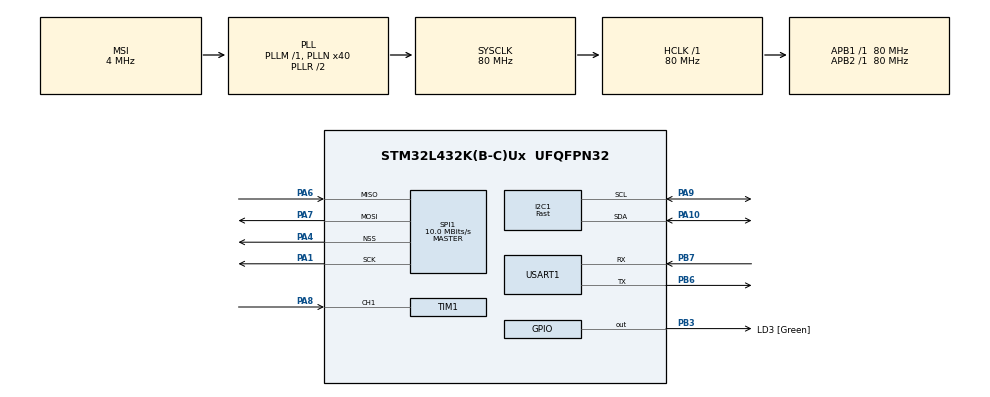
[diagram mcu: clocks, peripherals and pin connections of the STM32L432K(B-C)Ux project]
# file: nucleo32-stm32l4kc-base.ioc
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I2C1.I2C_Speed_Mode=I2C_Fast
I2C1.Timing=0x00702991
Mcu.Family=STM32L4
Mcu.Name=STM32L432K(B-C)Ux
Mcu.Package=UFQFPN32
NVIC.I2C1_ER_IRQn=true\:0\:0\:false\:false\:true\:true
NVIC.I2C1_EV_IRQn=true\:0\:0\:false\:false\:true\:true
NVIC.PriorityGroup=NVIC_PRIORITYGROUP_4
NVIC.SPI1_IRQn=true\:0\:0\:false\:false\:true\:true
NVIC.TIM1_CC_IRQn=true\:0\:0\:false\:false\:true\:true
NVIC.USART1_IRQn=true\:0\:0\:false\:false\:true\:true
PA0.GPIO_Label=MCO [High speed clock in]
PA0.Signal=RCC_CK_IN
PA1.Mode=Full_Duplex_Master
PA1.Signal=SPI1_SCK
PA10.Mode=I2C
PA10.Signal=I2C1_SDA
PA13\ (JTMS-SWDIO).GPIO_Label=SWDIO
PA13\ (JTMS-SWDIO).Signal=SYS_JTMS-SWDIO
PA14\ (JTCK-SWCLK).GPIO_Label=SWCLK
PA14\ (JTCK-SWCLK).Signal=SYS_JTCK-SWCLK
PA15\ (JTDI).GPIO_Label=VCP_RX
PA15\ (JTDI).Signal=USART2_RX
PA2.GPIO_Label=VCP_TX
PA2.Signal=USART2_TX
PA4.Mode=NSS_Signal_Hard_Output
PA4.Signal=SPI1_NSS
PA6.Mode=Full_Duplex_Master
PA6.Signal=SPI1_MISO
PA7.Mode=Full_Duplex_Master
PA7.Signal=SPI1_MOSI
PA8.Signal=S_TIM1_CH1
PA9.Mode=I2C
PA9.Signal=I2C1_SCL
PB3\ (JTDO-TRACESWO).GPIO_Label=LD3 [Green]
PB3\ (JTDO-TRACESWO).Signal=GPIO_Output
PB6.Mode=Asynchronous
PB6.Signal=USART1_TX
PB7.Mode=Asynchronous
PB7.Signal=USART1_RX
PC14-OSC32_IN\ (PC14).Signal=RCC_OSC32_IN
PC15-OSC32_OUT\ (PC15).Signal=RCC_OSC32_OUT
ProjectManager.HeapSize=0x200
ProjectManager.StackSize=0x400
ProjectManager.TargetToolchain=Makefile
RCC.AHBFreq_Value=80000000
RCC.APB1Freq_Value=80000000
RCC.APB1TimFreq_Value=80000000
RCC.APB2Freq_Value=80000000
RCC.APB2TimFreq_Value=80000000
RCC.CortexFreq_Value=80000000
RCC.HCLKFreq_Value=80000000
RCC.HSE_VALUE=8000000
RCC.HSI16_VALUE=16000000
RCC.HSI48_VALUE=48000000
RCC.HSI_VALUE=16000000
RCC.LSE_VALUE=32768
RCC.MSI_VALUE=4000000
RCC.PLLMUL=RCC_PLLMUL_4
RCC.PLLN=40
RCC.SYSCLKFreq_VALUE=80000000
RCC.SYSCLKSource=RCC_SYSCLKSOURCE_PLLCLK
RCC.VCOOutputFreq_Value=160000000
SH.S_TIM1_CH1.0=TIM1_CH1,Input_Capture1_from_TI1
SPI1.BaudRatePrescaler=SPI_BAUDRATEPRESCALER_8
SPI1.CalculateBaudRate=10.0 MBits/s
SPI1.Direction=SPI_DIRECTION_2LINES
SPI1.Mode=SPI_MODE_MASTER
SPI1.VirtualNSS=VM_NSSHARD
SPI1.VirtualType=VM_MASTER
TIM1.AutoReloadPreload=TIM_AUTORELOAD_PRELOAD_ENABLE
TIM1.Channel-Input_Capture1_from_TI1=TIM_CHANNEL_1
TIM1.Period=60000
TIM1.Prescaler=256
USART1.VirtualMode-Asynchronous=VM_ASYNC
VP_TIM1_VS_ClockSourceINT.Mode=Internal
board=NUCLEO-L432KC

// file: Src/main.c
/**
  ******************************************************************************
  * File Name          : main.c
  * Description        : Main program body
  ******************************************************************************
  ** This notice applies to any and all portions of this file
  * that are not between comment pairs USER CODE BEGIN and
  * USER CODE END. Other portions of this file, whether
  * inserted by the user or by software development tools
  * are owned by their respective copyright owners.
  *
  * COPYRIGHT(c) 2018 STMicroelectronics
  *
  * Redistribution and use in source and binary forms, with or without modification,
  * are permitted provided that the following conditions are met:
  *   1. Redistributions of source code must retain the above copyright notice,
  *      this list of conditions and the following disclaimer.
  *   2. Redistributions in binary form must reproduce the above copyright notice,
  *      this list of conditions and the following disclaimer in the documentation
  *      and/or other materials provided with the distribution.
  *   3. Neither the name of STMicroelectronics nor the names of its contributors
  *      may be used to endorse or promote products derived from this software
  *      without specific prior written permission.
  *
  * THIS SOFTWARE IS PROVIDED BY THE COPYRIGHT HOLDERS AND CONTRIBUTORS "AS IS"
  * AND ANY EXPRESS OR IMPLIED WARRANTIES, INCLUDING, BUT NOT LIMITED TO, THE
  * IMPLIED WARRANTIES OF MERCHANTABILITY AND FITNESS FOR A PARTICULAR PURPOSE ARE
  * DISCLAIMED. IN NO EVENT SHALL THE COPYRIGHT HOLDER OR CONTRIBUTORS BE LIABLE
  * FOR ANY DIRECT, INDIRECT, INCIDENTAL, SPECIAL, EXEMPLARY, OR CONSEQUENTIAL
  * DAMAGES (INCLUDING, BUT NOT LIMITED TO, PROCUREMENT OF SUBSTITUTE GOODS OR
  * SERVICES; LOSS OF USE, DATA, OR PROFITS; OR BUSINESS INTERRUPTION) HOWEVER
  * CAUSED AND ON ANY THEORY OF LIABILITY, WHETHER IN CONTRACT, STRICT LIABILITY,
  * OR TORT (INCLUDING NEGLIGENCE OR OTHERWISE) ARISING IN ANY WAY OUT OF THE USE
  * OF THIS SOFTWARE, EVEN IF ADVISED OF THE POSSIBILITY OF SUCH DAMAGE.
  *
  ******************************************************************************
  */

#include "main.h"
#include "stm32l4xx_hal.h"
#include "i2c.h"
#include "spi.h"
#include "tim.h"
#include "usart.h"
#include "gpio.h"

/* USER CODE BEGIN PV */
/* Private variables ---------------------------------------------------------*/

/* USER CODE END PV */

void SystemClock_Config(void);

/* USER CODE BEGIN PFP */
/* Private function prototypes -----------------------------------------------*/

/* USER CODE END PFP */

int main(void) {

    /* MCU Configuration----------------------------------------------------------*/

    /* Reset of all peripherals, Initializes the Flash interface and the Systick. */
    HAL_Init();

    /* Configure the system clock */
    SystemClock_Config();

    /* Initialize all configured peripherals */
    MX_GPIO_Init();
    MX_I2C1_Init();
    MX_SPI1_Init();
    MX_USART1_UART_Init();
    MX_TIM1_Init();

    /* Infinite loop */
    while (1) {

        while (1) {

            HAL_Delay(100);
            HAL_GPIO_TogglePin(LD3_GPIO_Port, LD3_Pin);
        }

    }

}

/** System Clock Configuration
*/
void SystemClock_Config(void) {

    RCC_OscInitTypeDef RCC_OscInitStruct;
    RCC_ClkInitTypeDef RCC_ClkInitStruct;
    RCC_PeriphCLKInitTypeDef PeriphClkInit;

    /**Initializes the CPU, AHB and APB busses clocks
    */
    RCC_OscInitStruct.OscillatorType = RCC_OSCILLATORTYPE_MSI;
    RCC_OscInitStruct.MSIState = RCC_MSI_ON;
    RCC_OscInitStruct.MSICalibrationValue = 0;
    RCC_OscInitStruct.MSIClockRange = RCC_MSIRANGE_6;
    RCC_OscInitStruct.PLL.PLLState = RCC_PLL_ON;
    RCC_OscInitStruct.PLL.PLLSource = RCC_PLLSOURCE_MSI;
    RCC_OscInitStruct.PLL.PLLM = 1;
    RCC_OscInitStruct.PLL.PLLN = 40;
    RCC_OscInitStruct.PLL.PLLP = RCC_PLLP_DIV7;
    RCC_OscInitStruct.PLL.PLLQ = RCC_PLLQ_DIV2;
    RCC_OscInitStruct.PLL.PLLR = RCC_PLLR_DIV2;
    if (HAL_RCC_OscConfig(&RCC_OscInitStruct) != HAL_OK) {
        _Error_Handler(__FILE__, __LINE__);
    }

    /**Initializes the CPU, AHB and APB busses clocks
    */
    RCC_ClkInitStruct.ClockType = RCC_CLOCKTYPE_HCLK | RCC_CLOCKTYPE_SYSCLK
                                  | RCC_CLOCKTYPE_PCLK1 | RCC_CLOCKTYPE_PCLK2;
    RCC_ClkInitStruct.SYSCLKSource = RCC_SYSCLKSOURCE_PLLCLK;
    RCC_ClkInitStruct.AHBCLKDivider = RCC_SYSCLK_DIV1;
    RCC_ClkInitStruct.APB1CLKDivider = RCC_HCLK_DIV1;
    RCC_ClkInitStruct.APB2CLKDivider = RCC_HCLK_DIV1;

    if (HAL_RCC_ClockConfig(&RCC_ClkInitStruct, FLASH_LATENCY_4) != HAL_OK) {
        _Error_Handler(__FILE__, __LINE__);
    }

    PeriphClkInit.PeriphClockSelection = RCC_PERIPHCLK_USART1 | RCC_PERIPHCLK_I2C1;
    PeriphClkInit.Usart1ClockSelection = RCC_USART1CLKSOURCE_PCLK2;
    PeriphClkInit.I2c1ClockSelection = RCC_I2C1CLKSOURCE_PCLK1;
    if (HAL_RCCEx_PeriphCLKConfig(&PeriphClkInit) != HAL_OK) {
        _Error_Handler(__FILE__, __LINE__);
    }

    /**Configure the main internal regulator output voltage
    */
    if (HAL_PWREx_ControlVoltageScaling(PWR_REGULATOR_VOLTAGE_SCALE1) != HAL_OK) {
        _Error_Handler(__FILE__, __LINE__);
    }

    /**Configure the Systick interrupt time
    */
    HAL_SYSTICK_Config(HAL_RCC_GetHCLKFreq() / 1000);

    /**Configure the Systick
    */
    HAL_SYSTICK_CLKSourceConfig(SYSTICK_CLKSOURCE_HCLK);

    /* SysTick_IRQn interrupt configuration */
    HAL_NVIC_SetPriority(SysTick_IRQn, 0, 0);
}

void _Error_Handler(char *file, int line) {
    /* USER CODE BEGIN Error_Handler_Debug */
    (void) file;
    (void) line;
    /* User can add his own implementation to report the HAL error return state */
    while (1) {
    }
    /* USER CODE END Error_Handler_Debug */
}

#ifdef USE_FULL_ASSERT

/**
   * @brief Reports the name of the source file and the source line number
   * where the assert_param error has occurred.
   * @param file: pointer to the source file name
   * @param line: assert_param error line source number
   * @retval None
   */
void assert_failed(uint8_t *file, uint32_t line) {
    /* USER CODE BEGIN 6 */

    (void) file;
    (void) line;
    /* User can add his own implementation to report the file name and line number,
      ex: printf("Wrong parameters value: file %s on line %d\r\n", file, line) */
    /* USER CODE END 6 */

}

#endif

/************************ (C) COPYRIGHT STMicroelectronics *****END OF FILE****/
